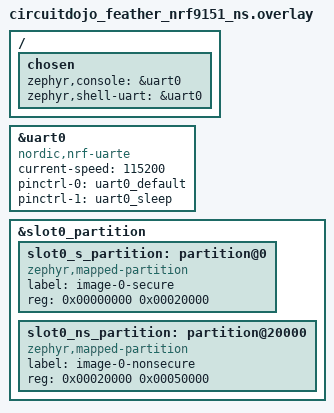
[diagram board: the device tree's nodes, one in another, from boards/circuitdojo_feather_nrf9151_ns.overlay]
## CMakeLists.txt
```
cmake_minimum_required(VERSION 3.20.0)

# This sample verifies the platform's certificate chain.
set(SAMPLE_TLS verify)
include(${CMAKE_CURRENT_SOURCE_DIR}/../common/app.cmake)

find_package(Zephyr REQUIRED HINTS $ENV{ZEPHYR_BASE})
project(asset_tracker)

include(${CMAKE_CURRENT_SOURCE_DIR}/../common/cert.cmake)

target_sources(app PRIVATE src/main.c src/shadow.c)

# gnss.c talks to nrf_modem_gnss, which exists only on the nRF91 modem.
if(CONFIG_ASSET_TRACKER_SIM_GPS)
  target_sources(app PRIVATE src/gnss_sim.c)
else()
  target_sources(app PRIVATE src/gnss.c)
endif()

include(${CMAKE_CURRENT_SOURCE_DIR}/../common/net.cmake)
```

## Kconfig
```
menu "Asset tracker sample"

config ASSET_TRACKER_SIM_GPS
  bool "Report a simulated track instead of real GNSS fixes" if SOC_SERIES_NRF91
  default y if !SOC_SERIES_NRF91
  help
    A real receiver exists only on the nRF91 modem, so every other board
    reports a fabricated circuit around the base coordinate below. On a
    Feather it is the indoor option, where GNSS will very likely never fix.
    A simulated sample reports gps_fix_quality 2 rather than 1, so a
    dashboard can never mistake it for a real fix.

if ASSET_TRACKER_SIM_GPS

config ASSET_TRACKER_SIM_BASE_LAT
  string "Simulated track centre latitude (decimal degrees)"
  default "45.523064"

config ASSET_TRACKER_SIM_BASE_LON
  string "Simulated track centre longitude (decimal degrees)"
  default "-122.676483"

config ASSET_TRACKER_SIM_RADIUS_M
  int "Simulated circuit radius (metres)"
  default 50
  help
    Small enough to read as an asset moving around one yard rather than a
    vehicle on a highway.

config ASSET_TRACKER_SIM_PERIOD_SEC
  int "Seconds per simulated lap"
  range 10 86400
  default 300
  help
    With the radius above, this is what sets the reported gps_speed_mps.

endif # ASSET_TRACKER_SIM_GPS

if !ASSET_TRACKER_SIM_GPS

config ASSET_TRACKER_GNSS_FIX_INTERVAL_SEC
  int "Seconds between periodic GNSS fixes"
  range 10 65535
  default 120
  help
    Periodic navigation leaves the modem more of the shared radio for LTE
    between fixes than continuous mode does.

config ASSET_TRACKER_GNSS_FIX_RETRY_SEC
  int "Seconds GNSS may search before abandoning one fix"
  range 0 65535
  default 120
  help
    Unbounded, the receiver keeps searching until the next interval even
    where a fix can never come.

endif # !ASSET_TRACKER_SIM_GPS

config ASSET_TRACKER_CONNECT_MAX_ROUNDS
  int "Network connect attempts before rebooting"
  default 5
  help
    Nothing else recovers a device that never reaches the network: the
    watchdog feeds on a successful report, and a modem inside its
    reset-loop restriction fails to attach once and then sits idle.

config ASSET_TRACKER_CONNECT_BACKOFF_BASE_SEC
  int "Backoff before the second connect attempt (seconds)"
  default 30
  help
    An attempt usually fails for a reason seconds will not clear, so the
    first retry already waits.

config ASSET_TRACKER_CONNECT_BACKOFF_MAX_SEC
  int "Backoff ceiling between connect attempts (seconds)"
  default 300
  help
    The backoff doubles each round up to this.

module = ASSET_TRACKER
module-str = Asset tracker sample
source "$(ZEPHYR_BASE)/subsys/logging/Kconfig.template.log_config"

endmenu

menu "Zephyr Kernel"
source "Kconfig.zephyr"
endmenu
```

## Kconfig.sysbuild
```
rsource "../Kconfig.sysbuild.signing"

# A Feather has nothing at address 0 without MCUboot, and boots TF-M through
# it. The ESP32-C6 board defaults to MCUboot; this sample stages no update, so
# a single image is enough there and on native_sim.
choice BOOTLOADER
	default BOOTLOADER_NONE if BOARD_ESP32C6_DEVKITC
	default BOOTLOADER_MCUBOOT if SOC_SERIES_NRF91
endchoice

source "share/sysbuild/Kconfig"
```

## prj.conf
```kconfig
# GNSS position reported as telemetry over the HTTPS connector, with the
# recovery options an unattended device needs. The endpoint and token belong
# in the git-ignored prj.local.conf.
CONFIG_PIGEON=y
CONFIG_PIGEON_CONNECTOR_HTTPS=y
# The modem's credential store outlives a reflash and is keyed by tag, so each
# sample here owns a distinct one rather than the shared default.
CONFIG_PIGEON_HTTPS_SEC_TAG=44

# Seven position keys, uptime and the boot's reset cause, plus a spare. Past
# the store's size a key is refused rather than queued, and the whole cycle is
# meant to ride one report.
CONFIG_PIGEON_TELEMETRY_MAX_KEYS=10

# Nobody is standing next to the asset: a fatal error reboots rather than
# halting, and the watchdog covers a liveness stall that raises none.
CONFIG_PIGEON_REBOOT_ON_FATAL=y
CONFIG_PIGEON_WATCHDOG=y

CONFIG_PICOLIBC=y
# The position is reported as decimal strings, so %f has to print.
CONFIG_PICOLIBC_IO_FLOAT=y
CONFIG_CBPRINTF_FP_SUPPORT=y
CONFIG_STD_C17=y
CONFIG_MISRA_SANE=y
CONFIG_SIZE_OPTIMIZATIONS=y

CONFIG_HEAP_MEM_POOL_SIZE=8192
CONFIG_MAIN_STACK_SIZE=8192
CONFIG_SYSTEM_WORKQUEUE_STACK_SIZE=4096
# Logging from the connection manager's event callbacks overflows the default.
CONFIG_NET_MGMT_EVENT_STACK_SIZE=2048

CONFIG_NETWORKING=y
CONFIG_NET_SOCKETS=y
CONFIG_NET_SOCKETS_SOCKOPT_TLS=y
CONFIG_NET_IPV4=y
CONFIG_NET_IPV6=y
CONFIG_NET_CONNECTION_MANAGER=y
CONFIG_NET_CONNECTION_MANAGER_MONITOR_STACK_SIZE=1024

CONFIG_LOG=y
CONFIG_LOG_DEFAULT_LEVEL=3
CONFIG_LOG_MODE_IMMEDIATE=y
# Lets the shadow's "log" field silence and restore logging at runtime.
CONFIG_LOG_RUNTIME_FILTERING=y
CONFIG_NET_LOG=y
```

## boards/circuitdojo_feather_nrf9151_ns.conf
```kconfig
# Beyond ../../common/boards/nrf91.conf.

# GPS has to be in the modem's system mode for it to interleave satellite
# search with LTE reception rather than one excluding the other.
CONFIG_LTE_NETWORK_MODE_LTE_M_GPS=y

# Power saving mode asks the network for longer idle windows, which is the
# time GNSS gets to search in. The parameters nRF's own GNSS sample requests.
CONFIG_LTE_LC_PSM_MODULE=y
CONFIG_LTE_PSM_REQ=y
CONFIG_LTE_PSM_REQ_RPTAU="00101000"
CONFIG_LTE_PSM_REQ_RAT="00000011"

# Nordic's antenna library gates the GNSS low-noise amplifier only for its own
# boards; without this command the receiver tracks no satellites here.
CONFIG_MODEM_ANTENNA=y
CONFIG_MODEM_ANTENNA_AT_COEX0="AT\%XCOEX0=1,1,1565,1586"
```

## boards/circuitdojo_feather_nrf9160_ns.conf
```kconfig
# Board-specific config for the Circuit Dojo nRF9160 Feather (/ns variant).
# Mirrors https_init's board conf of the same name (minus the modem-trace
# UART bits this sample doesn't use -- see the overlay), with one addition:
# RTT console/log backend instead of UART. This board's UART TX pin is
# proven dead at the bench-wiring level (TX->CP2102N never reaches the
# host), but SWD/J-Link works fine, so route all console+log output over
# RTT instead -- full log visibility with zero UART dependency. Same
# CONFIG_USE_SEGGER_RTT/CONFIG_LOG_BACKEND_RTT this repo's own
# embedded-departure-board sibling project already uses for its MCUboot
# sub-image on this exact board.

# Allow writing to the (internal) flash at runtime. Kept even without
# MCUmgr/FOTA in this sample -- see the 9151 board conf's identical note.
CONFIG_MPU_ALLOW_FLASH_WRITE=y

# Align the max FD entry to NRF_MODEM_MAX_SOCKET_COUNT(8)
CONFIG_ZVFS_OPEN_MAX=8
CONFIG_NET_SOCKETS_POLL_MAX=8

# Disable Duplicate Address Detection (DAD)
# due to not being properly implemented for offloaded interfaces.
CONFIG_NET_IPV6_NBR_CACHE=n
CONFIG_NET_IPV6_MLD=n

# Connection Manager and Connectivity layer
CONFIG_NRF_MODEM_LIB_NET_IF=y

# AT Host
CONFIG_UART_INTERRUPT_DRIVEN=y

# Modem key management -- see the 9151 board conf's identical note: nRF91
# TLS sockets are offloaded to the modem regardless of this board, so this
# must be y for connection_manager.c's provision_cert() to actually reach
# the modem's own credential store.
CONFIG_MODEM_KEY_MGMT=y

# GNSS antenna/LNA coexistence config (found the hard way -- real hardware
# read gps_sats=0 indefinitely, antenna attached, until this was added).
# Nordic's modem_antenna library (nrf/lib/modem_antenna/Kconfig) only
# defaults this on for Nordic's own DK/Thingy91 boards -- this board isn't
# in that allowlist, so nothing issues the LNA-gating AT command unless an
# app explicitly opts in. Circuit Dojo's own reference GPS sample
# (circuitdojo/nrf9160-feather-examples-and-drivers, samples/gps board
# confs) sets exactly this value for the 9160/9151/9161 Feather family, and
# it matches Nordic's own MODEM_ANTENNA_GNSS_ONBOARD default -- this
# board's GNSS antenna path needs the same LNA-gating window as the
# reference DK boards, just not auto-configured for a non-Nordic board. No
# XMAGPIO needed -- Circuit Dojo's own sample doesn't set one for this
# board family either, implying the antenna switch here isn't MAGPIO-driven.
CONFIG_MODEM_ANTENNA=y
CONFIG_MODEM_ANTENNA_AT_COEX0="AT\%XCOEX0=1,1,1565,1586"

# TF-M configurations
CONFIG_BUILD_WITH_TFM=y
CONFIG_TFM_PROFILE_TYPE_NOT_SET=y
CONFIG_TFM_CMAKE_BUILD_TYPE_RELEASE=y

# UART configuration (common) -- still needed by the modem/AT-host path
# (nRF91 modem UART framing, unrelated to this board's console), just not
# used as the console/log sink anymore (see RTT below).
CONFIG_SERIAL=y
CONFIG_UART_ASYNC_API=y

# RTT console + log backend, replacing UART console on this board (see this
# file's header comment for why). CONFIG_CONSOLE stays on (RTT_CONSOLE
# depends on it) -- only the backing driver moves off UART.
CONFIG_UART_CONSOLE=n
CONFIG_USE_SEGGER_RTT=y
CONFIG_RTT_CONSOLE=y
CONFIG_LOG_BACKEND_RTT=y
# Non-blocking: an app that's actually out doing its job (unlike MCUboot's
# brief recovery-window run) must never stall waiting for a debugger to
# attach and start reading the RTT buffer.
CONFIG_SEGGER_RTT_MODE_NO_BLOCK_TRIM=y
```

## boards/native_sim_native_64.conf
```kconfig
# Beyond ../../common/boards/native_sim.conf.

# Verifying the platform's certificate chain in mbedTLS.
CONFIG_MBEDTLS_X509_CRT_PARSE_C=y
# The CA ships as PEM; without this mbedTLS accepts only DER.
CONFIG_MBEDTLS_PEM_PARSE_C=y
# Without SNI the edge answers the ClientHello with handshake_failure.
CONFIG_MBEDTLS_SSL_SERVER_NAME_INDICATION=y
CONFIG_MBEDTLS_KEY_EXCHANGE_ECDHE_RSA_ENABLED=y
CONFIG_MBEDTLS_KEY_EXCHANGE_ECDHE_ECDSA_ENABLED=y
CONFIG_PSA_WANT_ALG_ECDH=y
CONFIG_PSA_WANT_ALG_ECDSA=y
CONFIG_PSA_WANT_ALG_RSA_PKCS1V15_SIGN=y
CONFIG_PSA_WANT_ALG_SHA_256=y
# The root is P-384 and signs with SHA-384; the leaf is P-256.
CONFIG_PSA_WANT_ALG_SHA_384=y
CONFIG_PSA_WANT_ECC_SECP_R1_256=y
CONFIG_PSA_WANT_ECC_SECP_R1_384=y
CONFIG_PSA_WANT_KEY_TYPE_ECC_PUBLIC_KEY=y
CONFIG_PSA_WANT_KEY_TYPE_ECC_KEY_PAIR_IMPORT=y
# ECDHE generates a fresh key pair per handshake, a separate PSA want.
CONFIG_PSA_WANT_KEY_TYPE_ECC_KEY_PAIR_GENERATE=y
CONFIG_PSA_WANT_KEY_TYPE_RSA_PUBLIC_KEY=y
# ECDHE-RSA depends on an RSA key-pair want even for a verify-only client.
CONFIG_PSA_WANT_KEY_TYPE_RSA_KEY_PAIR_IMPORT=y
CONFIG_PSA_WANT_ALG_GCM=y
CONFIG_PSA_WANT_KEY_TYPE_AES=y
# TLS 1.2 derives the master secret with its own PSA algorithm.
CONFIG_PSA_WANT_ALG_TLS12_PRF=y
CONFIG_PSA_WANT_ALG_HMAC=y
CONFIG_PSA_WANT_KEY_TYPE_HMAC=y
```

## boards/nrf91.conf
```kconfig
# Both nRF91 Feathers, on top of ../../common/boards/nrf91.conf.

# GPS has to be in the modem's system mode for it to interleave satellite
# search with LTE reception rather than one excluding the other.
CONFIG_LTE_NETWORK_MODE_LTE_M_GPS=y

# Power saving mode asks the network for longer idle windows, which is the
# time GNSS gets to search in. The parameters nRF's own GNSS sample requests.
CONFIG_LTE_LC_PSM_MODULE=y
CONFIG_LTE_PSM_REQ=y
CONFIG_LTE_PSM_REQ_RPTAU="00101000"
CONFIG_LTE_PSM_REQ_RAT="00000011"

# Nordic's antenna library gates the GNSS low-noise amplifier only for its own
# boards; without this command the receiver tracks no satellites here.
CONFIG_MODEM_ANTENNA=y
CONFIG_MODEM_ANTENNA_AT_COEX0="AT\%XCOEX0=1,1,1565,1586"
```

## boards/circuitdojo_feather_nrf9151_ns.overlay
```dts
/* Matches the baud MCUboot prints at, so one terminal reads both images. */
&uart0 {
  status = "okay";
  compatible = "nordic,nrf-uarte";
  current-speed = <115200>;
  pinctrl-0 = <&uart0_default>;
  pinctrl-1 = <&uart0_sleep>;
  pinctrl-names = "default", "sleep";
};

/* The stock 256/192 KiB secure/non-secure split leaves TF-M most of its share
 * unused while this application overflows its own. The slot total is
 * unchanged, so MCUboot's overlay needs nothing. */
/delete-node/ &slot0_s_partition;
/delete-node/ &slot0_ns_partition;

&slot0_partition {
  slot0_s_partition: partition@0 {
    compatible = "zephyr,mapped-partition";
    label = "image-0-secure";
    reg = <0x00000000 0x00020000>;
  };

  slot0_ns_partition: partition@20000 {
    compatible = "zephyr,mapped-partition";
    label = "image-0-nonsecure";
    reg = <0x00020000 0x00050000>;
  };
};

/ {
  chosen {
    zephyr,console = &uart0;
    zephyr,shell-uart = &uart0;
  };
};
```

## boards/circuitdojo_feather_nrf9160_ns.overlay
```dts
/* Matches the baud MCUboot prints at, so one terminal reads both images. */
&uart0 {
  status = "okay";
  compatible = "nordic,nrf-uarte";
  current-speed = <1000000>;
  pinctrl-0 = <&uart0_default>;
  pinctrl-1 = <&uart0_sleep>;
  pinctrl-names = "default", "sleep";
};

/* The stock 256/192 KiB secure/non-secure split leaves TF-M most of its share
 * unused while this application overflows its own. The slot total is
 * unchanged, so MCUboot's overlay needs nothing. */
/delete-node/ &slot0_s_partition;
/delete-node/ &slot0_ns_partition;

&slot0_partition {
  slot0_s_partition: partition@0 {
    compatible = "zephyr,mapped-partition";
    label = "image-0-secure";
    reg = <0x00000000 0x00020000>;
  };

  slot0_ns_partition: partition@20000 {
    compatible = "zephyr,mapped-partition";
    label = "image-0-nonsecure";
    reg = <0x00020000 0x00050000>;
  };
};

/ {
  chosen {
    zephyr,console = &uart0;
    zephyr,shell-uart = &uart0;
  };
};
```

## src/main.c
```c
#include <errno.h>
#include <pigeon.h>
#include <zephyr/kernel.h>
#include <zephyr/logging/log.h>
#include <zephyr/sys/util.h>

#include "gnss.h"
#include "net_connect.h"
#include "shadow.h"

LOG_MODULE_REGISTER(main);

/* The platform's root CA, terminated because mbedTLS parses PEM as a string. */
static const char ca_cert[] = {
#include "GTS_Root_R4.crt.hex"
    0x00
};

BUILD_ASSERT(sizeof(ca_cert) < KB(4), "the modem's credential store caps a certificate at 4 KiB");

/* Nothing else recovers an asset that never reaches the network: the watchdog
 * feeds on a successful report, so it never fires, and there is no operator
 * where the device is. A fresh boot clears what a retry often cannot. */
static int connect_with_retry(void) {
  uint32_t backoff_sec = CONFIG_ASSET_TRACKER_CONNECT_BACKOFF_BASE_SEC;

  for (int round = 1; round <= CONFIG_ASSET_TRACKER_CONNECT_MAX_ROUNDS; round++) {
    int err = net_connect();

    if (!err) {
      return 0;
    }

    LOG_ERR(
        "Connect attempt %d/%d failed: %d", round, CONFIG_ASSET_TRACKER_CONNECT_MAX_ROUNDS, err
    );

    if (round == CONFIG_ASSET_TRACKER_CONNECT_MAX_ROUNDS) {
      break;
    }

    LOG_WRN("Retrying in %u s", backoff_sec);
    k_sleep(K_SECONDS(backoff_sec));
    backoff_sec = MIN(backoff_sec * 2, CONFIG_ASSET_TRACKER_CONNECT_BACKOFF_MAX_SEC);
  }

  return -ENOTCONN;
}

int main(void) {
  if (IS_ENABLED(CONFIG_ASSET_TRACKER_SIM_GPS)) {
    LOG_WRN(
        "Simulated position: every fix this build reports is fabricated and "
        "carries gps_fix_quality=%d",
        TRACKER_FIX_SIMULATED
    );
  }

  int err = net_prepare();

  if (err) {
    return err;
  }

  err = net_install_ca(CONFIG_PIGEON_HTTPS_SEC_TAG, ca_cert, sizeof(ca_cert));
  if (err) {
    return err;
  }

  if (connect_with_retry()) {
    pigeon_reboot();
  }

  /* The endpoint and token come from Kconfig. device_id only names this
   * device in its own logs; the platform identifies it by its token. */
  struct pigeon_config config = {
      .device_id = "asset-tracker-sample",
      .connector = {.type = PIGEON_CONNECTOR_HTTPS},
  };

  err = pigeon_init(&config);
  if (err) {
    net_disconnect();
    return err;
  }

  /* A failure here is not fatal: every poll still reports no fix, which is
   * also what a receiver that cannot see the sky reports. */
  err = tracker_gnss_init();
  if (err) {
    LOG_ERR("Position source failed to start: %d", err);
  }

  shadow_loop();

  return net_disconnect();
}
```

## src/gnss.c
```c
/** @headerfile gnss.h
 *  The nRF91 modem's own GNSS receiver, read through nrf_modem_gnss.
 */
#include "gnss.h"

#include <modem/lte_lc.h>
#include <nrf_modem_gnss.h>
#include <string.h>
#include <zephyr/kernel.h>
#include <zephyr/logging/log.h>

LOG_MODULE_REGISTER(gnss, CONFIG_ASSET_TRACKER_LOG_LEVEL);

/* GPS has to be in the modem's system mode for the receiver to run at all;
 * without it every call below succeeds and no fix ever arrives. */
BUILD_ASSERT(
    IS_ENABLED(CONFIG_LTE_NETWORK_MODE_LTE_M_GPS) ||
        IS_ENABLED(CONFIG_LTE_NETWORK_MODE_NBIOT_GPS) ||
        IS_ENABLED(CONFIG_LTE_NETWORK_MODE_LTE_M_NBIOT_GPS),
    "the modem's system mode must include GPS"
);

static struct k_mutex pvt_lock;
static struct nrf_modem_gnss_pvt_data_frame last_pvt;
static bool have_pvt;

static void gnss_event_handler(int event) {
  /* No NMEA stream is subscribed and no assistance is requested, so a
   * position frame is the only event this sample asked for. */
  if (event != NRF_MODEM_GNSS_EVT_PVT) {
    return;
  }

  struct nrf_modem_gnss_pvt_data_frame pvt;

  if (nrf_modem_gnss_read(&pvt, sizeof(pvt), NRF_MODEM_GNSS_DATA_PVT) != 0) {
    LOG_WRN("Failed to read the position frame");
    return;
  }

  k_mutex_lock(&pvt_lock, K_FOREVER);
  last_pvt = pvt;
  have_pvt = true;
  k_mutex_unlock(&pvt_lock);
}

int tracker_gnss_init(void) {
  k_mutex_init(&pvt_lock);

  /* Attaching to LTE activates LTE alone, and GNSS stays off: every
   * nrf_modem_gnss call then fails with -NRF_EACCES. This mode is additive
   * and leaves the LTE connection alone. */
  int err = lte_lc_func_mode_set(LTE_LC_FUNC_MODE_ACTIVATE_GNSS);

  if (err) {
    LOG_ERR("Failed to activate the GNSS functional mode: %d", err);
    return err;
  }

  err = nrf_modem_gnss_event_handler_set(gnss_event_handler);
  if (err) {
    LOG_ERR("Failed to set the GNSS event handler: %d", err);
    return err;
  }

  err = nrf_modem_gnss_fix_interval_set(CONFIG_ASSET_TRACKER_GNSS_FIX_INTERVAL_SEC);
  if (err) {
    LOG_ERR("Failed to set the GNSS fix interval: %d", err);
    return err;
  }

  err = nrf_modem_gnss_fix_retry_set(CONFIG_ASSET_TRACKER_GNSS_FIX_RETRY_SEC);
  if (err) {
    LOG_ERR("Failed to set the GNSS fix retry timeout: %d", err);
    return err;
  }

  err = nrf_modem_gnss_start();
  if (err) {
    LOG_ERR("Failed to start GNSS: %d", err);
    return err;
  }

  LOG_INF(
      "GNSS started: a fix every %d s, abandoned after %d s of searching",
      CONFIG_ASSET_TRACKER_GNSS_FIX_INTERVAL_SEC, CONFIG_ASSET_TRACKER_GNSS_FIX_RETRY_SEC
  );

  return 0;
}

void tracker_gnss_get_latest(struct tracker_position* out) {
  memset(out, 0, sizeof(*out));

  k_mutex_lock(&pvt_lock, K_FOREVER);

  if (!have_pvt) {
    k_mutex_unlock(&pvt_lock);
    LOG_INF("No position frame received yet");
    return;
  }

  struct nrf_modem_gnss_pvt_data_frame pvt = last_pvt;

  k_mutex_unlock(&pvt_lock);

  /* Counted whether or not each satellite was used in the fix, so "nothing
   * in view" and "six in view, still no fix" stay distinguishable. */
  int sats = 0;

  for (int i = 0; i < NRF_MODEM_GNSS_MAX_SATELLITES; i++) {
    if (pvt.sv[i].sv != 0) {
      sats++;
    }
  }

  out->sats = sats;

  if ((pvt.flags & NRF_MODEM_GNSS_PVT_FLAG_FIX_VALID) == 0) {
    out->fix_quality = TRACKER_FIX_NONE;
    return;
  }

  out->fix_quality = TRACKER_FIX_REAL;
  out->latitude = pvt.latitude;
  out->longitude = pvt.longitude;
  out->altitude_m = pvt.altitude;
  out->speed_mps = pvt.speed;
  out->heading_deg = pvt.heading;
}
```

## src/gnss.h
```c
/** @file gnss.h
 *  @brief The tracker's position source: the nRF91's own GNSS receiver, or
 *  the simulated track every board without one reports.
 */
#ifndef GNSS_H
#define GNSS_H

/** Reported as the gps_fix_quality telemetry key. */
enum tracker_fix_quality {
  /** No valid fix yet, the expected steady state indoors. */
  TRACKER_FIX_NONE = 0,
  TRACKER_FIX_REAL = 1,
  /** A fabricated position, so a dashboard never reads it as a real fix. */
  TRACKER_FIX_SIMULATED = 2,
};

/** One position sample, real or simulated. */
struct tracker_position {
  double latitude;
  double longitude;
  float altitude_m;
  float speed_mps;
  float heading_deg;
  /** Satellites tracked, whether or not each was used in the fix; a receiver
   *  still searching reports these with no position. */
  int sats;
  enum tracker_fix_quality fix_quality;
};

/** Starts the position source. Call it once the network is up: the modem only
 *  accepts the GNSS functional mode with its library already running. */
int tracker_gnss_init(void);

/** Fills out with the latest sample. A real receiver leaves it at
 *  TRACKER_FIX_NONE until it fixes; the simulated track always has one. */
void tracker_gnss_get_latest(struct tracker_position* out);

#endif
```

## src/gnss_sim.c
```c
/** @headerfile gnss.h
 *  A fabricated circuit around a configured coordinate, for a board with no
 *  receiver and for an indoor Feather where a fix will never come.
 */
#include "gnss.h"

#include <math.h>
#include <stdlib.h>
#include <zephyr/kernel.h>
#include <zephyr/logging/log.h>

LOG_MODULE_REGISTER(gnss, CONFIG_ASSET_TRACKER_LOG_LEVEL);

/* Picolibc leaves M_PI out under a strict C standard. */
#define PI 3.14159265358979323846
#define EARTH_RADIUS_M 6371000.0

/* Plausible and fixed: the track models motion, not sky visibility. */
#define SIM_SATS 9

static double base_lat;
static double base_lon;
static double base_lat_rad;

int tracker_gnss_init(void) {
  base_lat = strtod(CONFIG_ASSET_TRACKER_SIM_BASE_LAT, NULL);
  base_lon = strtod(CONFIG_ASSET_TRACKER_SIM_BASE_LON, NULL);
  base_lat_rad = base_lat * PI / 180.0;

  LOG_INF(
      "Simulated track: a %d m circuit around %.6f,%.6f, one lap every %d s",
      CONFIG_ASSET_TRACKER_SIM_RADIUS_M, base_lat, base_lon,
      CONFIG_ASSET_TRACKER_SIM_PERIOD_SEC
  );

  return 0;
}

void tracker_gnss_get_latest(struct tracker_position* out) {
  double elapsed_s = (double)k_uptime_get() / 1000.0;
  double period_s = (double)CONFIG_ASSET_TRACKER_SIM_PERIOD_SEC;
  double angle = 2.0 * PI * fmod(elapsed_s, period_s) / period_s;
  double radius_m = (double)CONFIG_ASSET_TRACKER_SIM_RADIUS_M;

  /* A flat-earth offset, which at this radius is indistinguishable from the
   * geodesic one. */
  double lat_offset_deg = (radius_m / EARTH_RADIUS_M) * (180.0 / PI) * cos(angle);
  double lon_offset_deg =
      (radius_m / EARTH_RADIUS_M) * (180.0 / PI) * sin(angle) / cos(base_lat_rad);

  out->latitude = base_lat + lat_offset_deg;
  out->longitude = base_lon + lon_offset_deg;
  /* A gentle bob, so a graph of altitude is not a flat line. */
  out->altitude_m = 50.0f + (float)(3.0 * sin(angle));
  out->speed_mps = (float)(2.0 * PI * radius_m / period_s);
  /* Motion is tangent to the radius, hence the quarter turn. */
  out->heading_deg = fmodf((float)(angle * 180.0 / PI) + 90.0f, 360.0f);
  out->sats = SIM_SATS;
  out->fix_quality = TRACKER_FIX_SIMULATED;
}
```

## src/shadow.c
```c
/** @headerfile shadow.h */
#include "shadow.h"

#include <pigeon.h>
#include <string.h>
#include <zephyr/data/json.h>
#include <zephyr/kernel.h>
#include <zephyr/logging/log.h>
#include <zephyr/logging/log_ctrl.h>
#include <zephyr/sys/printk.h>

#include "gnss.h"
#include "net_connect.h"

LOG_MODULE_REGISTER(shadow);

/* target_config is opaque JSON to the library; this application decides what
 * its keys mean. */
struct app_shadow_config {
  bool log;
  int telemetry_interval;
  bool reboot;
};

static const struct json_obj_descr app_shadow_config_descr[] = {
    JSON_OBJ_DESCR_PRIM(struct app_shadow_config, log, JSON_TOK_TRUE),
    JSON_OBJ_DESCR_PRIM(struct app_shadow_config, telemetry_interval, JSON_TOK_NUMBER),
    JSON_OBJ_DESCR_PRIM(struct app_shadow_config, reboot, JSON_TOK_TRUE),
};

/* Defaults applied before the first sync of a boot. Nothing persists across
 * reboots, so every boot re-applies the platform's target from here. */
static struct app_shadow_config current_config = {
    .log = false,
    .telemetry_interval = 60,
    .reboot = false,
};

/* One call covers every module, so the shadow's "log" field really silences
 * and restores output. */
static void set_all_log_levels(uint32_t level) {
  uint32_t module_count = log_src_cnt_get(Z_LOG_LOCAL_DOMAIN_ID);

  for (uint32_t i = 0; i < module_count; i++) {
    log_filter_set(NULL, Z_LOG_LOCAL_DOMAIN_ID, (int16_t)i, level);
  }
}

static void queue_metric(const char* key, const char* value) {
  int err = pigeon_telemetry_set(key, value);

  if (err) {
    LOG_WRN("Failed to queue telemetry '%s': %d", key, err);
  }
}

/* Fix quality and satellite count are reported even with no fix, so a
 * dashboard can tell a device searching in a basement from a silent one. The
 * position itself is only meaningful once there is a fix. */
static void queue_position(void) {
  struct tracker_position pos;

  tracker_gnss_get_latest(&pos);

  char buf[32];

  snprintk(buf, sizeof(buf), "%d", (int)pos.fix_quality);
  queue_metric("gps_fix_quality", buf);

  snprintk(buf, sizeof(buf), "%d", pos.sats);
  queue_metric("gps_sats", buf);

  if (pos.fix_quality == TRACKER_FIX_NONE) {
    LOG_INF("No fix yet, %d satellites tracked; position not reported", pos.sats);
    return;
  }

  snprintk(buf, sizeof(buf), "%.6f", pos.latitude);
  queue_metric("gps_lat", buf);

  snprintk(buf, sizeof(buf), "%.6f", pos.longitude);
  queue_metric("gps_lon", buf);

  snprintk(buf, sizeof(buf), "%.1f", (double)pos.altitude_m);
  queue_metric("gps_alt_m", buf);

  snprintk(buf, sizeof(buf), "%.2f", (double)pos.speed_mps);
  queue_metric("gps_speed_mps", buf);

  snprintk(buf, sizeof(buf), "%.1f", (double)pos.heading_deg);
  queue_metric("gps_heading_deg", buf);

  LOG_INF(
      "Position (%s): %.6f,%.6f alt=%.1fm speed=%.2fm/s heading=%.1fdeg sats=%d",
      pos.fix_quality == TRACKER_FIX_SIMULATED ? "simulated" : "fix", pos.latitude, pos.longitude,
      (double)pos.altitude_m, (double)pos.speed_mps, (double)pos.heading_deg, pos.sats
  );
}

/* Every key of a cycle rides one report, which over LTE-M is one TLS
 * handshake instead of eight. */
static void report_telemetry(void) {
  char buf[21];

  snprintk(buf, sizeof(buf), "%lld", (long long)(k_uptime_get() / 1000));
  queue_metric("uptime_s", buf);

  queue_position();

  int err = pigeon_telemetry_flush();

  if (err) {
    LOG_WRN("Telemetry report failed: %d; the queued keys wait for the next poll", err);
  }
}

int shadow_sync(void) {
  struct pigeon_shadow_doc doc;
  int err = pigeon_shadow_get(&doc);

  if (err) {
    LOG_ERR("Failed to fetch device shadow: %d", err);
    return err;
  }

  LOG_INF(
      "Shadow fetched: target_version=%d current_version=%d updated_at=%lld", doc.target_version,
      doc.current_version, doc.updated_at
  );

  report_telemetry();

  if (doc.target_version == doc.current_version) {
    LOG_INF("Shadow already converged at version %d; nothing to apply", doc.current_version);
    return 0;
  }

  /* json_obj_parse() edits its input, and target_config only lives until the
   * next fetch. */
  char config_buf[CONFIG_PIGEON_SHADOW_CONFIG_MAX];

  strncpy(config_buf, doc.target_config, sizeof(config_buf) - 1);
  config_buf[sizeof(config_buf) - 1] = '\0';

  /* Keys absent from a partial update keep their current value. reboot is a
   * one-shot command and always starts false. */
  struct app_shadow_config target = current_config;
  target.reboot = false;

  int64_t decoded = json_obj_parse(
      config_buf, strlen(config_buf), app_shadow_config_descr, ARRAY_SIZE(app_shadow_config_descr),
      &target
  );

  if (decoded < 0) {
    LOG_ERR("Failed to parse shadow target_config '%s': %lld", doc.target_config, decoded);
    return (int)decoded;
  }

  if (target.log != current_config.log) {
    LOG_INF(
        "Shadow v%d: log %s -> %s", doc.target_version, current_config.log ? "true" : "false",
        target.log ? "true" : "false"
    );
    set_all_log_levels(target.log ? CONFIG_LOG_DEFAULT_LEVEL : LOG_LEVEL_NONE);
  }

  if (target.telemetry_interval != current_config.telemetry_interval) {
    LOG_INF(
        "Shadow v%d: telemetry_interval %d -> %d", doc.target_version,
        current_config.telemetry_interval, target.telemetry_interval
    );
  }

  current_config.log = target.log;
  current_config.telemetry_interval = target.telemetry_interval;

  LOG_INF(
      "Applied shadow v%d: log=%s telemetry_interval=%d", doc.target_version,
      current_config.log ? "true" : "false", current_config.telemetry_interval
  );

  char report_buf[128];
  int encode_err = json_obj_encode_buf(
      app_shadow_config_descr, ARRAY_SIZE(app_shadow_config_descr), &current_config, report_buf,
      sizeof(report_buf)
  );

  if (encode_err) {
    LOG_ERR("Failed to encode current_config for shadow report: %d", encode_err);
  } else {
    int report_err = pigeon_shadow_report(doc.target_version, report_buf);

    if (report_err) {
      LOG_WRN("Shadow report-back failed: %d", report_err);
    } else {
      LOG_INF("Reported current_config back to platform at v%d", doc.target_version);
    }
  }

  /* "reboot" is a command, not state: kept out of current_config so it is
   * never seen as unchanged and re-run on every poll. net_disconnect() comes
   * first because a modem reset without a graceful power-off trips its
   * reset-loop protection. */
  if (target.reboot) {
    LOG_WRN("Shadow v%d requested reboot; disconnecting and rebooting now", doc.target_version);
    net_disconnect();
    pigeon_reboot();
  }

  return 0;
}

void shadow_loop(void) {
  while (1) {
    shadow_sync();

    LOG_INF("Next shadow poll in %d s", current_config.telemetry_interval);
    k_sleep(K_SECONDS(current_config.telemetry_interval));
  }
}
```

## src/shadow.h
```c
/** @file shadow.h
 *  @brief Shadow sync: fetch, apply, report back, plus position telemetry.
 */
#ifndef SHADOW_H
#define SHADOW_H

/** Fetches the shadow, reports uptime and the latest position, applies a newer
 *  target_config and reports the result. Returns 0 whether or not anything
 *  changed, negative on a transport or parse failure. */
int shadow_sync(void);

/** Runs shadow_sync() forever, sleeping the shadow's own telemetry_interval
 *  between polls. */
void shadow_loop(void);

#endif
```
